# owm_reva_me13 register map
Registers are 32-bit, read-write, no defined reset value unless marked. A register's access mark holds for its fields unless they carry their own. Offsets are from the block's base; lines under a group give offsets from that group; [hi:lo] are bit positions; {n}, {i} and the like mark numbered series; 'fields as' and 'values as' point back to an identical list; <NAME> marks a mode.

## Memory map
0x4003D000 OWM size 0x1000 — 1-Wire Master Interface.

## Interrupts
67 OneWire (OWM)

## OWM — 1-Wire Master Interface.
Base 0x4003D000
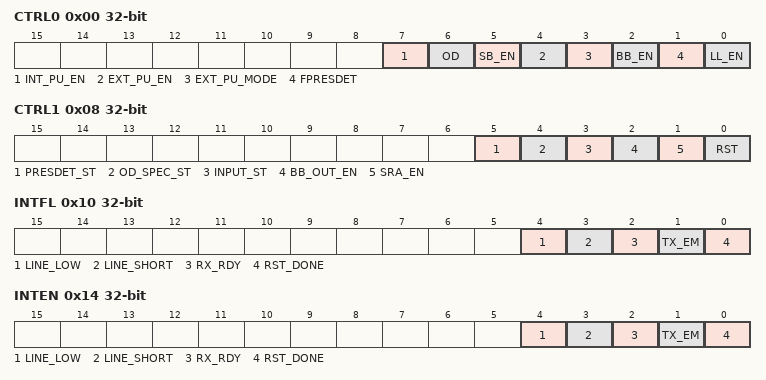
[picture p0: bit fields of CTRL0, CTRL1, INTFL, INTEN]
0x00 CTRL0 — 1-Wire Master Control Register.
  [7] INT_PU_EN — Enable intenral pullup.
  [6] OD — Enables overdrive speed for 1-Wire operations.
  [5] SB_EN — Enable Single Bit TX/RX Mode.
  [4] EXT_PU_EN — Enable External Pullup.
  [3] EXT_PU_MODE — Provide an extra output control to control an external pullup.
  [2] BB_EN — Bit Bang Enable.
  [1] FPRESDET — Force Line During Presence Detect.
  [0] LL_EN — Enable Long Line Mode.
0x04 CLKDIV — 1-Wire Master Clock Divisor.
  [7:0] DIVISOR — Clock Divisor for 1Mhz.
0x08 CTRL1 — 1-Wire Master Control/Status.
  [5] PRESDET_ST ro — Presence Pulse Detected.
  [4] OD_SPEC_ST ro — Overdrive Spec Mode.
  [3] INPUT_ST ro — OW Input State.
  [2] BB_OUT_EN — Bit Bang Output Enable.
  [1] SRA_EN — Enable SRA Mode.
  [0] RST — Start OW Reset.
0x0C DATA — 1-Wire Master Data Buffer.
  [7:0] DATA — TX/RX Buffer.
0x10 INTFL — 1-Wire Master Interrupt Flags.
  [4] LINE_LOW — OW Line Low Detected Interrupt Flag.
  [3] LINE_SHORT — OW Line Short Detected Interrupt Flag.
  [2] RX_RDY — RX Data Ready Interrupt Flag
  [1] TX_EM — TX Data Empty Interrupt Flag.
  [0] RST_DONE — OW Reset Sequence Completed.
0x14 INTEN — 1-Wire Master Interrupt Enables.
  [4] LINE_LOW write-1-clears — OW Line Low Detected Interrupt Enable.
  [3] LINE_SHORT write-1-clears — OW Line Short Detected Interrupt Enable.
  [2] RX_RDY write-1-clears — Rx Data Ready Interrupt Enable.
  [1] TX_EM write-1-clears — Tx Data Empty Interrupt Enable.
  [0] RST_DONE write-1-clears — OW Reset Sequence Completed.
